/* Version Date Author */
/* V01 20200727 M.Flemming */
/* Mahle Expansion Valve MVTM */
/* all signals clima => expansionvalve use prefix control*/
/* all signals expansionvalve => clima use prefix Status expect communication error */

LIN_description_file;
LIN_protocol_version = "2.2";
LIN_language_version = "2.2";
LIN_speed = 19.2 kbps;
Channel_name = "net1";

Nodes {
  Master: CLIMA, 5 ms, 0.1 ms ;
  Slaves: MVTM_1 ;
}

Signals {
  StatusAliveCounterMVTM: 3, 7, MVTM_1, CLIMA ;
  CommunicationErrorMVTM: 1, 0, MVTM_1, CLIMA ;
  ControlCalibrationMVTM: 2, 3, CLIMA, MVTM_1 ;
  ControlPositionMVTM: 12, 4095, CLIMA, MVTM_1 ;
  StatusDiag1MVTM: 4, 15, MVTM_1, CLIMA ;
  StatusDiag2MVTM: 16, 65535, MVTM_1, CLIMA ;
  StatusCalibrationMVTM: 2, 3, MVTM_1, CLIMA ;
  StatusPositionMVTM: 12, 4095, MVTM_1, CLIMA ;
}

Frames {
  ControlMVTM: 44, CLIMA, 4 {
    ControlPositionMVTM, 0 ;
    ControlCalibrationMVTM, 14 ;
  }
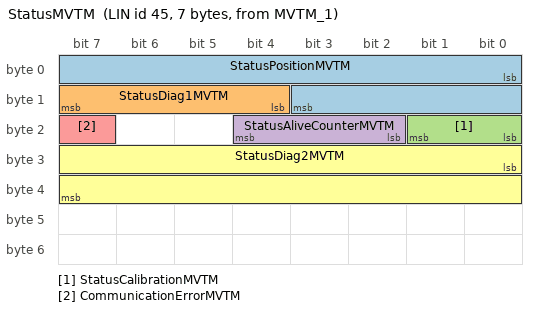
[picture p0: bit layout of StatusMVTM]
  StatusMVTM: 45, MVTM_1, 7 {
    StatusPositionMVTM, 0 ;
    StatusDiag1MVTM, 12 ;
    StatusCalibrationMVTM, 16 ;
    StatusAliveCounterMVTM, 18 ;
    CommunicationErrorMVTM, 23 ;
    StatusDiag2MVTM, 24 ;
  }
}

Node_attributes {
  MVTM_1{
    LIN_protocol = "2.2" ;
    configured_NAD = 0x64 ;
    initial_NAD = 0x64 ;
    product_id = 0x91, 0x700, 0 ;
    response_error = CommunicationErrorMVTM ;
    P2_min = 50 ms ;
    ST_min = 0 ms ;
    N_As_timeout = 1000 ms ;
    N_Cr_timeout = 1000 ms ;
    configurable_frames {
      ControlMVTM ;
      StatusMVTM ;
    }
  }
}

Schedule_tables {
 MVTM_1s {
    StatusMVTM delay 500 ms ;
    ControlMVTM delay 500 ms ;
  }
 MVTM_10ms {
    StatusMVTM delay 10 ms ;
    ControlMVTM delay 10 ms ;
  }
 MVTM_100ms {
    StatusMVTM delay 100 ms ;
    ControlMVTM delay 100 ms ;
  }
}

Signal_encoding_types {
  CommunicationErrorMVTM {
    logical_value, 0, "error_inactive" ;
    logical_value, 1, "error_active" ;
  }
  ControlCalibrationMVTM {
    logical_value, 0, "CC_calibration_not_requested" ;
    logical_value, 1, "CC_calibration_requested" ;
    logical_value, 3, "CC_signal_not_available" ;
  }
  ControlPositionMVTM {
    physical_value, 0, 4000, 0.025, 0, "%" ;
    logical_value, 4092, "CP_reserved" ;
    logical_value, 4093, "CP_signal_not_available" ;
    logical_value, 4094, "CP_signal_error" ;
    logical_value, 4095, "CP_signal_NA" ;
  }
  StatusAliveCounterMVTM {
    physical_value, 0, 6, 1, 0 ;
    logical_value, 7, "SAC_signal_not_available" ;
  }
  StatusCalibrationMVTM {
    logical_value, 0, "SC_calibration_inactive" ;
    logical_value, 1, "SC_calibration_running" ;
    logical_value, 3, "SC_signal_not_available" ;
  }
  StatusDiag1MVTM {
    logical_value, 0, "SD_ok" ;
    logical_value, 1, "SD_position_invalid" ;
    logical_value, 2, "SD_position_valid" ;
    logical_value, 4, "SD_diagnostic_active" ;
    logical_value, 15, "SD_signal_not_available" ;
  }
  StatusDiag2MVTM {
    physical_value, 0, 65535, 1, 0, "SD2_decoding_not_supported" ;
  }
  StatusPositionMVTM {
    physical_value, 0, 4000, 0.025, 0, "%" ;
    logical_value, 4092, "SP_reserved" ;
    logical_value, 4093, "SP_signal_not_available" ;
    logical_value, 4094, "SP_signal_error" ;
    logical_value, 4095, "SP_signal_NA" ;
  }
}

Signal_representation {
  CommunicationErrorMVTM: CommunicationErrorMVTM ;
  ControlCalibrationMVTM: ControlCalibrationMVTM ;
  ControlPositionMVTM: ControlPositionMVTM ;
  StatusAliveCounterMVTM: StatusAliveCounterMVTM ;
  StatusCalibrationMVTM: StatusCalibrationMVTM ;
  StatusDiag1MVTM: StatusDiag1MVTM ;
  StatusDiag2MVTM: StatusDiag2MVTM ;
  StatusPositionMVTM: StatusPositionMVTM ;
}
